AUTOSAR XML (schema 4-0-3)
package /ComponentTypes
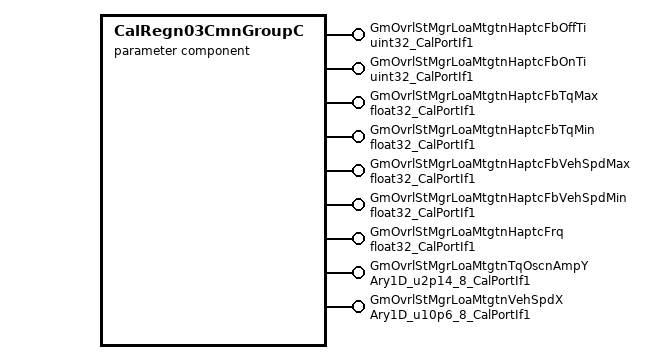
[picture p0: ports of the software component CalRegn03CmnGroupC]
  parameter sw component type CalRegn03CmnGroupC
    9 x provide port:
      GmOvrlStMgrLoaMtgtnHaptcFbOffTi: parameter-provide-com-spec{init-value=5000, parameter=Val}, provided-interface=uint32_CalPortIf1
      GmOvrlStMgrLoaMtgtnHaptcFbOnTi: parameter-provide-com-spec{init-value=800, parameter=Val}, provided-interface=uint32_CalPortIf1
      GmOvrlStMgrLoaMtgtnHaptcFbTqMax: parameter-provide-com-spec{init-value=8, parameter=Val}, provided-interface=float32_CalPortIf1
      GmOvrlStMgrLoaMtgtnHaptcFbTqMin: parameter-provide-com-spec{init-value=0.5, parameter=Val}, provided-interface=float32_CalPortIf1
      GmOvrlStMgrLoaMtgtnHaptcFbVehSpdMax: parameter-provide-com-spec{init-value=128, parameter=Val}, provided-interface=float32_CalPortIf1
      GmOvrlStMgrLoaMtgtnHaptcFbVehSpdMin: parameter-provide-com-spec{init-value=2, parameter=Val}, provided-interface=float32_CalPortIf1
      GmOvrlStMgrLoaMtgtnHaptcFrq: parameter-provide-com-spec{init-value=10, parameter=Val}, provided-interface=float32_CalPortIf1
      GmOvrlStMgrLoaMtgtnTqOscnAmpY: parameter-provide-com-spec{init-value=8 x 8192, parameter=Ary1D}, provided-interface=Ary1D_u2p14_8_CalPortIf1
      GmOvrlStMgrLoaMtgtnVehSpdX: parameter-provide-com-spec{init-value=[320, 640, 1280, 2560, 3840, 5120, 6400, 7680], parameter=Ary1D}, provided-interface=Ary1D_u10p6_8_CalPortIf1
